AUTOSAR XML (schema 00044)
package /ComponentTypes
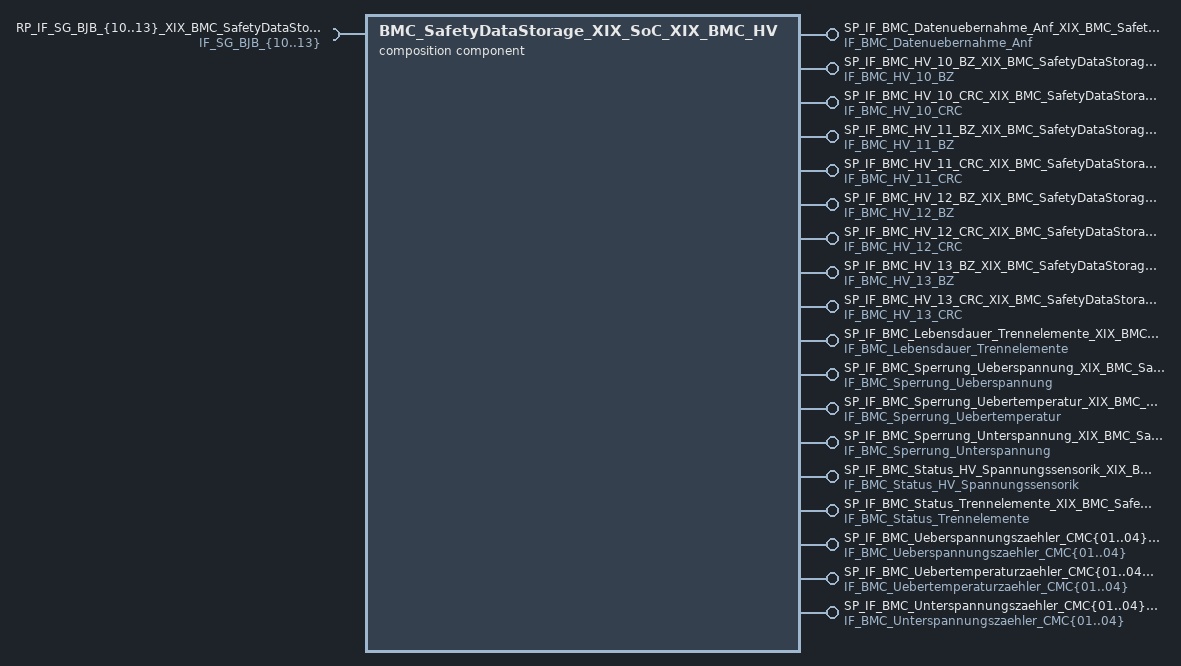
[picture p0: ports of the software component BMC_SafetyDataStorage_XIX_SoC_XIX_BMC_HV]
  composition sw component type BMC_SafetyDataStorage_XIX_SoC_XIX_BMC_HV
    27 x provide port:
      SP_IF_BMC_Datenuebernahme_Anf_XIX_BMC_SafetyDataStorage_XIX_SoC_XIX_BMC_HV: nonqueued-sender-com-spec=DE_BMC_Datenuebernahme_Anf, provided-interface=IF_BMC_Datenuebernahme_Anf
      SP_IF_BMC_HV_10_BZ_XIX_BMC_SafetyDataStorage_XIX_SoC_XIX_BMC_HV: nonqueued-sender-com-spec=DE_BMC_HV_10_BZ, provided-interface=IF_BMC_HV_10_BZ
      SP_IF_BMC_HV_10_CRC_XIX_BMC_SafetyDataStorage_XIX_SoC_XIX_BMC_HV: nonqueued-sender-com-spec=DE_BMC_HV_10_CRC, provided-interface=IF_BMC_HV_10_CRC
      SP_IF_BMC_HV_11_BZ_XIX_BMC_SafetyDataStorage_XIX_SoC_XIX_BMC_HV: nonqueued-sender-com-spec=DE_BMC_HV_11_BZ, provided-interface=IF_BMC_HV_11_BZ
      SP_IF_BMC_HV_11_CRC_XIX_BMC_SafetyDataStorage_XIX_SoC_XIX_BMC_HV: nonqueued-sender-com-spec=DE_BMC_HV_11_CRC, provided-interface=IF_BMC_HV_11_CRC
      SP_IF_BMC_HV_12_BZ_XIX_BMC_SafetyDataStorage_XIX_SoC_XIX_BMC_HV: nonqueued-sender-com-spec=DE_BMC_HV_12_BZ, provided-interface=IF_BMC_HV_12_BZ
      SP_IF_BMC_HV_12_CRC_XIX_BMC_SafetyDataStorage_XIX_SoC_XIX_BMC_HV: nonqueued-sender-com-spec=DE_BMC_HV_12_CRC, provided-interface=IF_BMC_HV_12_CRC
      SP_IF_BMC_HV_13_BZ_XIX_BMC_SafetyDataStorage_XIX_SoC_XIX_BMC_HV: nonqueued-sender-com-spec=DE_BMC_HV_13_BZ, provided-interface=IF_BMC_HV_13_BZ
      SP_IF_BMC_HV_13_CRC_XIX_BMC_SafetyDataStorage_XIX_SoC_XIX_BMC_HV: nonqueued-sender-com-spec=DE_BMC_HV_13_CRC, provided-interface=IF_BMC_HV_13_CRC
      SP_IF_BMC_Lebensdauer_Trennelemente_XIX_BMC_SafetyDataStorage_XIX_SoC_XIX_BMC_HV: nonqueued-sender-com-spec=DE_BMC_Lebensdauer_Trennelemente, provided-interface=IF_BMC_Lebensdauer_Trennelemente
      SP_IF_BMC_Sperrung_Ueberspannung_XIX_BMC_SafetyDataStorage_XIX_SoC_XIX_BMC_HV: nonqueued-sender-com-spec=DE_BMC_Sperrung_Ueberspannung, provided-interface=IF_BMC_Sperrung_Ueberspannung
      SP_IF_BMC_Sperrung_Uebertemperatur_XIX_BMC_SafetyDataStorage_XIX_SoC_XIX_BMC_HV: nonqueued-sender-com-spec=DE_BMC_Sperrung_Uebertemperatur, provided-interface=IF_BMC_Sperrung_Uebertemperatur
      SP_IF_BMC_Sperrung_Unterspannung_XIX_BMC_SafetyDataStorage_XIX_SoC_XIX_BMC_HV: nonqueued-sender-com-spec=DE_BMC_Sperrung_Unterspannung, provided-interface=IF_BMC_Sperrung_Unterspannung
      SP_IF_BMC_Status_HV_Spannungssensorik_XIX_BMC_SafetyDataStorage_XIX_SoC_XIX_BMC_HV: nonqueued-sender-com-spec=DE_BMC_Status_HV_Spannungssensorik, provided-interface=IF_BMC_Status_HV_Spannungssensorik
      SP_IF_BMC_Status_Trennelemente_XIX_BMC_SafetyDataStorage_XIX_SoC_XIX_BMC_HV: nonqueued-sender-com-spec=DE_BMC_Status_Trennelemente, provided-interface=IF_BMC_Status_Trennelemente
      SP_IF_BMC_Ueberspannungszaehler_CMC{01..04}_XIX_BMC_SafetyDataStorage_XIX_SoC_XIX_BMC_HV: nonqueued-sender-com-spec=DE_BMC_Ueberspannungszaehler_CMC{01..04}, provided-interface=IF_BMC_Ueberspannungszaehler_CMC{01..04}
      SP_IF_BMC_Uebertemperaturzaehler_CMC{01..04}_XIX_BMC_SafetyDataStorage_XIX_SoC_XIX_BMC_HV: nonqueued-sender-com-spec=DE_BMC_Uebertemperaturzaehler_CMC{01..04}, provided-interface=IF_BMC_Uebertemperaturzaehler_CMC{01..04}
      SP_IF_BMC_Unterspannungszaehler_CMC{01..04}_XIX_BMC_SafetyDataStorage_XIX_SoC_XIX_BMC_HV: nonqueued-sender-com-spec=DE_BMC_Unterspannungszaehler_CMC{01..04}, provided-interface=IF_BMC_Unterspannungszaehler_CMC{01..04}
    4 x require port:
      RP_IF_SG_BJB_{10..13}_XIX_BMC_SafetyDataStorage_XIX_SoC_XIX_BMC_HV: nonqueued-receiver-com-spec=DE_SG_BJB_{10..13}, required-interface=IF_SG_BJB_{10..13}
